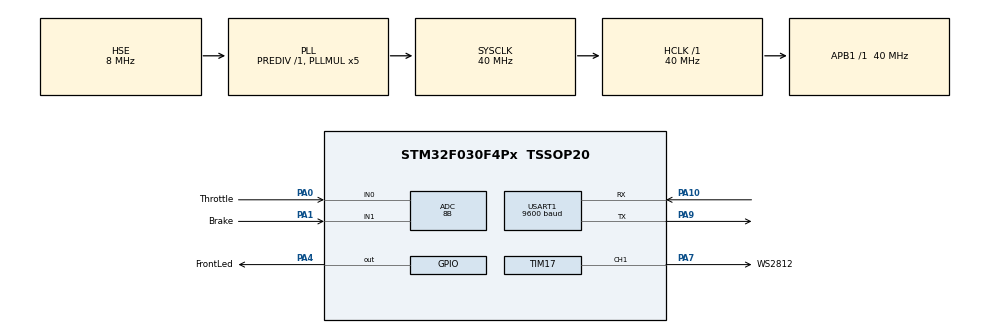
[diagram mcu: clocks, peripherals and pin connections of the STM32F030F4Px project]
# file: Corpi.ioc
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ADC.ClockPrescaler=ADC_CLOCK_SYNC_PCLK_DIV4
ADC.ContinuousConvMode=ENABLE
ADC.DMAContinuousRequests=ENABLE
ADC.Resolution=ADC_RESOLUTION_8B
ADC.SamplingTime=ADC_SAMPLETIME_239CYCLES_5
Dma.ADC.3.Direction=DMA_PERIPH_TO_MEMORY
Dma.ADC.3.Instance=DMA1_Channel1
Dma.ADC.3.MemDataAlignment=DMA_MDATAALIGN_WORD
Dma.ADC.3.MemInc=DMA_MINC_ENABLE
Dma.ADC.3.Mode=DMA_CIRCULAR
Dma.ADC.3.PeriphDataAlignment=DMA_PDATAALIGN_WORD
Dma.ADC.3.PeriphInc=DMA_PINC_DISABLE
Dma.ADC.3.Priority=DMA_PRIORITY_LOW
Dma.Request0=TIM17_CH1/UP
Dma.Request1=USART1_RX
Dma.Request2=USART1_TX
Dma.Request3=ADC
Dma.TIM17_CH1/UP.0.Direction=DMA_MEMORY_TO_PERIPH
Dma.TIM17_CH1/UP.0.Instance=DMA1_Channel2
Dma.TIM17_CH1/UP.0.MemDataAlignment=DMA_MDATAALIGN_HALFWORD
Dma.TIM17_CH1/UP.0.MemInc=DMA_MINC_ENABLE
Dma.TIM17_CH1/UP.0.Mode=DMA_NORMAL
Dma.TIM17_CH1/UP.0.PeriphDataAlignment=DMA_PDATAALIGN_HALFWORD
Dma.TIM17_CH1/UP.0.PeriphInc=DMA_PINC_DISABLE
Dma.TIM17_CH1/UP.0.Priority=DMA_PRIORITY_LOW
Dma.USART1_RX.1.Direction=DMA_PERIPH_TO_MEMORY
Dma.USART1_RX.1.Instance=DMA1_Channel3
Dma.USART1_RX.1.MemDataAlignment=DMA_MDATAALIGN_BYTE
Dma.USART1_RX.1.MemInc=DMA_MINC_ENABLE
Dma.USART1_RX.1.Mode=DMA_NORMAL
Dma.USART1_RX.1.PeriphDataAlignment=DMA_PDATAALIGN_BYTE
Dma.USART1_RX.1.PeriphInc=DMA_PINC_DISABLE
Dma.USART1_RX.1.Priority=DMA_PRIORITY_LOW
Dma.USART1_TX.2.Direction=DMA_MEMORY_TO_PERIPH
Dma.USART1_TX.2.Instance=DMA1_Channel4
Dma.USART1_TX.2.MemDataAlignment=DMA_MDATAALIGN_BYTE
Dma.USART1_TX.2.MemInc=DMA_MINC_ENABLE
Dma.USART1_TX.2.Mode=DMA_NORMAL
Dma.USART1_TX.2.PeriphDataAlignment=DMA_PDATAALIGN_BYTE
Dma.USART1_TX.2.PeriphInc=DMA_PINC_DISABLE
Dma.USART1_TX.2.Priority=DMA_PRIORITY_LOW
Mcu.Family=STM32F0
Mcu.Name=STM32F030F4Px
Mcu.Package=TSSOP20
NVIC.DMA1_Channel1_IRQn=true\:0\:0\:false\:false\:true\:false\:true
NVIC.DMA1_Channel2_3_IRQn=true\:0\:0\:false\:false\:true\:false\:true
NVIC.DMA1_Channel4_5_IRQn=true\:0\:0\:false\:false\:true\:false\:true
NVIC.USART1_IRQn=true\:0\:0\:false\:false\:true\:true\:true
PA0.GPIO_Label=Throttle
PA0.Mode=IN0
PA0.Signal=ADC_IN0
PA1.GPIO_Label=Brake
PA1.Mode=IN1
PA1.Signal=ADC_IN1
PA10.Mode=Asynchronous
PA10.Signal=USART1_RX
PA13.Mode=Serial_Wire
PA13.Signal=SYS_SWDIO
PA14.Mode=Serial_Wire
PA14.Signal=SYS_SWCLK
PA4.GPIO_Label=FrontLed
PA4.Signal=GPIO_Output
PA7.GPIO_Label=WS2812
PA7.Signal=S_TIM17_CH1
PA9.Mode=Asynchronous
PA9.Signal=USART1_TX
PF0-OSC_IN.Mode=HSE-External-Oscillator
PF0-OSC_IN.Signal=RCC_OSC_IN
PF1-OSC_OUT.Mode=HSE-External-Oscillator
PF1-OSC_OUT.Signal=RCC_OSC_OUT
ProjectManager.HeapSize=0x200
ProjectManager.StackSize=0x400
ProjectManager.TargetToolchain=STM32CubeIDE
RCC.AHBFreq_Value=40000000
RCC.APB1Freq_Value=40000000
RCC.APB1TimFreq_Value=40000000
RCC.HCLKFreq_Value=40000000
RCC.PLLMUL=RCC_PLL_MUL5
RCC.PLLSourceVirtual=RCC_PLLSOURCE_HSE
RCC.SYSCLKFreq_VALUE=40000000
RCC.SYSCLKSource=RCC_SYSCLKSOURCE_PLLCLK
SH.S_TIM17_CH1.0=TIM17_CH1,PWM Generation1 CH1
TIM17.Channel=TIM_CHANNEL_1
TIM17.Period=50-1
USART1.BaudRate=9600
USART1.VirtualMode-Asynchronous=VM_ASYNC
VP_TIM17_VS_ClockSourceINT.Mode=Enable_Timer
board=custom

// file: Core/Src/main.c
/* USER CODE BEGIN Header */
/**
  ******************************************************************************
  * @file           : main.c
  * @brief          : Main program body
  ******************************************************************************
  * @attention
  *
  * Copyright (c) 2022 STMicroelectronics.
  * All rights reserved.
  *
  * This software is licensed under terms that can be found in the LICENSE file
  * in the root directory of this software component.
  * If no LICENSE file comes with this software, it is provided AS-IS.
  *
  ******************************************************************************
  */
/* USER CODE END Header */
#include "main.h"

/* USER CODE BEGIN Includes */
#include "APP.h"
/* USER CODE END Includes */

ADC_HandleTypeDef hadc;
DMA_HandleTypeDef hdma_adc;

TIM_HandleTypeDef htim17;
DMA_HandleTypeDef hdma_tim17_ch1_up;

UART_HandleTypeDef huart1;
DMA_HandleTypeDef hdma_usart1_rx;
DMA_HandleTypeDef hdma_usart1_tx;

void SystemClock_Config(void);
static void MX_GPIO_Init(void);
static void MX_DMA_Init(void);
static void MX_TIM17_Init(void);
static void MX_USART1_UART_Init(void);
static void MX_ADC_Init(void);

int main(void)
{

  /* MCU Configuration--------------------------------------------------------*/

  /* Reset of all peripherals, Initializes the Flash interface and the Systick. */
  HAL_Init();

  /* Configure the system clock */
  SystemClock_Config();

  /* Initialize all configured peripherals */
  MX_GPIO_Init();
  MX_DMA_Init();
  MX_TIM17_Init();
  MX_USART1_UART_Init();
  MX_ADC_Init();
  /* USER CODE BEGIN 2 */
  APP_init();
  /* USER CODE END 2 */

  /* Infinite loop */
  /* USER CODE BEGIN WHILE */
  while (1)
  {
	APP_while();
    /* USER CODE END WHILE */

  }
}

void SystemClock_Config(void)
{
  RCC_OscInitTypeDef RCC_OscInitStruct = {0};
  RCC_ClkInitTypeDef RCC_ClkInitStruct = {0};
  RCC_PeriphCLKInitTypeDef PeriphClkInit = {0};

  /** Initializes the RCC Oscillators according to the specified parameters
  * in the RCC_OscInitTypeDef structure.
  */
  RCC_OscInitStruct.OscillatorType = RCC_OSCILLATORTYPE_HSE;
  RCC_OscInitStruct.HSEState = RCC_HSE_ON;
  RCC_OscInitStruct.PLL.PLLState = RCC_PLL_ON;
  RCC_OscInitStruct.PLL.PLLSource = RCC_PLLSOURCE_HSE;
  RCC_OscInitStruct.PLL.PLLMUL = RCC_PLL_MUL5;
  RCC_OscInitStruct.PLL.PREDIV = RCC_PREDIV_DIV1;
  if (HAL_RCC_OscConfig(&RCC_OscInitStruct) != HAL_OK)
  {
    Error_Handler();
  }
  /** Initializes the CPU, AHB and APB buses clocks
  */
  RCC_ClkInitStruct.ClockType = RCC_CLOCKTYPE_HCLK|RCC_CLOCKTYPE_SYSCLK
                              |RCC_CLOCKTYPE_PCLK1;
  RCC_ClkInitStruct.SYSCLKSource = RCC_SYSCLKSOURCE_PLLCLK;
  RCC_ClkInitStruct.AHBCLKDivider = RCC_SYSCLK_DIV1;
  RCC_ClkInitStruct.APB1CLKDivider = RCC_HCLK_DIV1;

  if (HAL_RCC_ClockConfig(&RCC_ClkInitStruct, FLASH_LATENCY_1) != HAL_OK)
  {
    Error_Handler();
  }
  PeriphClkInit.PeriphClockSelection = RCC_PERIPHCLK_USART1;
  PeriphClkInit.Usart1ClockSelection = RCC_USART1CLKSOURCE_PCLK1;
  if (HAL_RCCEx_PeriphCLKConfig(&PeriphClkInit) != HAL_OK)
  {
    Error_Handler();
  }
}

static void MX_ADC_Init(void)
{

  ADC_ChannelConfTypeDef sConfig = {0};

  /** Configure the global features of the ADC (Clock, Resolution, Data Alignment and number of conversion)
  */
  hadc.Instance = ADC1;
  hadc.Init.ClockPrescaler = ADC_CLOCK_SYNC_PCLK_DIV4;
  hadc.Init.Resolution = ADC_RESOLUTION_8B;
  hadc.Init.DataAlign = ADC_DATAALIGN_RIGHT;
  hadc.Init.ScanConvMode = ADC_SCAN_DIRECTION_FORWARD;
  hadc.Init.EOCSelection = ADC_EOC_SINGLE_CONV;
  hadc.Init.LowPowerAutoWait = DISABLE;
  hadc.Init.LowPowerAutoPowerOff = DISABLE;
  hadc.Init.ContinuousConvMode = ENABLE;
  hadc.Init.DiscontinuousConvMode = DISABLE;
  hadc.Init.ExternalTrigConv = ADC_SOFTWARE_START;
  hadc.Init.ExternalTrigConvEdge = ADC_EXTERNALTRIGCONVEDGE_NONE;
  hadc.Init.DMAContinuousRequests = ENABLE;
  hadc.Init.Overrun = ADC_OVR_DATA_PRESERVED;
  if (HAL_ADC_Init(&hadc) != HAL_OK)
  {
    Error_Handler();
  }
  /** Configure for the selected ADC regular channel to be converted.
  */
  sConfig.Channel = ADC_CHANNEL_0;
  sConfig.Rank = ADC_RANK_CHANNEL_NUMBER;
  sConfig.SamplingTime = ADC_SAMPLETIME_239CYCLES_5;
  if (HAL_ADC_ConfigChannel(&hadc, &sConfig) != HAL_OK)
  {
    Error_Handler();
  }
  /** Configure for the selected ADC regular channel to be converted.
  */
  sConfig.Channel = ADC_CHANNEL_1;
  if (HAL_ADC_ConfigChannel(&hadc, &sConfig) != HAL_OK)
  {
    Error_Handler();
  }

}

static void MX_TIM17_Init(void)
{

  TIM_OC_InitTypeDef sConfigOC = {0};
  TIM_BreakDeadTimeConfigTypeDef sBreakDeadTimeConfig = {0};

  htim17.Instance = TIM17;
  htim17.Init.Prescaler = 0;
  htim17.Init.CounterMode = TIM_COUNTERMODE_UP;
  htim17.Init.Period = 50-1;
  htim17.Init.ClockDivision = TIM_CLOCKDIVISION_DIV1;
  htim17.Init.RepetitionCounter = 0;
  htim17.Init.AutoReloadPreload = TIM_AUTORELOAD_PRELOAD_DISABLE;
  if (HAL_TIM_Base_Init(&htim17) != HAL_OK)
  {
    Error_Handler();
  }
  if (HAL_TIM_PWM_Init(&htim17) != HAL_OK)
  {
    Error_Handler();
  }
  sConfigOC.OCMode = TIM_OCMODE_PWM1;
  sConfigOC.Pulse = 0;
  sConfigOC.OCPolarity = TIM_OCPOLARITY_HIGH;
  sConfigOC.OCNPolarity = TIM_OCNPOLARITY_HIGH;
  sConfigOC.OCFastMode = TIM_OCFAST_DISABLE;
  sConfigOC.OCIdleState = TIM_OCIDLESTATE_RESET;
  sConfigOC.OCNIdleState = TIM_OCNIDLESTATE_RESET;
  if (HAL_TIM_PWM_ConfigChannel(&htim17, &sConfigOC, TIM_CHANNEL_1) != HAL_OK)
  {
    Error_Handler();
  }
  sBreakDeadTimeConfig.OffStateRunMode = TIM_OSSR_DISABLE;
  sBreakDeadTimeConfig.OffStateIDLEMode = TIM_OSSI_DISABLE;
  sBreakDeadTimeConfig.LockLevel = TIM_LOCKLEVEL_OFF;
  sBreakDeadTimeConfig.DeadTime = 0;
  sBreakDeadTimeConfig.BreakState = TIM_BREAK_DISABLE;
  sBreakDeadTimeConfig.BreakPolarity = TIM_BREAKPOLARITY_HIGH;
  sBreakDeadTimeConfig.AutomaticOutput = TIM_AUTOMATICOUTPUT_DISABLE;
  if (HAL_TIMEx_ConfigBreakDeadTime(&htim17, &sBreakDeadTimeConfig) != HAL_OK)
  {
    Error_Handler();
  }
  HAL_TIM_MspPostInit(&htim17);

}

static void MX_USART1_UART_Init(void)
{

  huart1.Instance = USART1;
  huart1.Init.BaudRate = 9600;
  huart1.Init.WordLength = UART_WORDLENGTH_8B;
  huart1.Init.StopBits = UART_STOPBITS_1;
  huart1.Init.Parity = UART_PARITY_NONE;
  huart1.Init.Mode = UART_MODE_TX_RX;
  huart1.Init.HwFlowCtl = UART_HWCONTROL_NONE;
  huart1.Init.OverSampling = UART_OVERSAMPLING_16;
  huart1.Init.OneBitSampling = UART_ONE_BIT_SAMPLE_DISABLE;
  huart1.AdvancedInit.AdvFeatureInit = UART_ADVFEATURE_NO_INIT;
  if (HAL_UART_Init(&huart1) != HAL_OK)
  {
    Error_Handler();
  }

}

static void MX_DMA_Init(void)
{

  /* DMA controller clock enable */
  __HAL_RCC_DMA1_CLK_ENABLE();

  /* DMA interrupt init */
  /* DMA1_Channel1_IRQn interrupt configuration */
  HAL_NVIC_SetPriority(DMA1_Channel1_IRQn, 0, 0);
  HAL_NVIC_EnableIRQ(DMA1_Channel1_IRQn);
  /* DMA1_Channel2_3_IRQn interrupt configuration */
  HAL_NVIC_SetPriority(DMA1_Channel2_3_IRQn, 0, 0);
  HAL_NVIC_EnableIRQ(DMA1_Channel2_3_IRQn);
  /* DMA1_Channel4_5_IRQn interrupt configuration */
  HAL_NVIC_SetPriority(DMA1_Channel4_5_IRQn, 0, 0);
  HAL_NVIC_EnableIRQ(DMA1_Channel4_5_IRQn);

}

static void MX_GPIO_Init(void)
{
  GPIO_InitTypeDef GPIO_InitStruct = {0};

  /* GPIO Ports Clock Enable */
  __HAL_RCC_GPIOF_CLK_ENABLE();
  __HAL_RCC_GPIOA_CLK_ENABLE();

  /*Configure GPIO pin Output Level */
  HAL_GPIO_WritePin(FrontLed_GPIO_Port, FrontLed_Pin, GPIO_PIN_RESET);

  /*Configure GPIO pin : FrontLed_Pin */
  GPIO_InitStruct.Pin = FrontLed_Pin;
  GPIO_InitStruct.Mode = GPIO_MODE_OUTPUT_PP;
  GPIO_InitStruct.Pull = GPIO_NOPULL;
  GPIO_InitStruct.Speed = GPIO_SPEED_FREQ_LOW;
  HAL_GPIO_Init(FrontLed_GPIO_Port, &GPIO_InitStruct);

}

void Error_Handler(void)
{
  __disable_irq();
  while (1)
  {
  }
}
